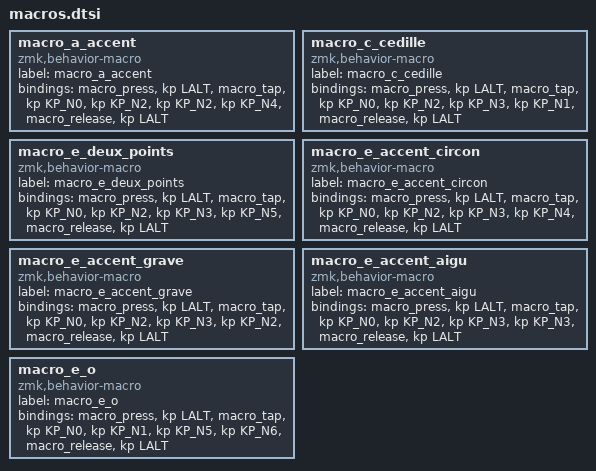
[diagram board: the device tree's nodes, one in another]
macro_a_accent: macro_a_accent{
compatible = "zmk,behavior-macro";
label = "macro_a_accent";
#binding-cells = <0>;
bindings = <&macro_press &kp LALT>, <&macro_tap &kp KP_N0 &kp KP_N2 &kp KP_N2 &kp KP_N4>, <&macro_release &kp LALT>;
};
macro_c_cedille: macro_c_cedille{
compatible = "zmk,behavior-macro";
label = "macro_c_cedille";
#binding-cells = <0>;
bindings = <&macro_press &kp LALT>, <&macro_tap &kp KP_N0 &kp KP_N2 &kp KP_N3 &kp KP_N1>, <&macro_release &kp LALT>;
};
macro_e_deux_points: macro_e_deux_points{
compatible = "zmk,behavior-macro";
label = "macro_e_deux_points";
#binding-cells = <0>;
bindings = <&macro_press &kp LALT>, <&macro_tap &kp KP_N0 &kp KP_N2 &kp KP_N3 &kp KP_N5>, <&macro_release &kp LALT>;
};
macro_e_accent_circon: macro_e_accent_circon{
compatible = "zmk,behavior-macro";
label = "macro_e_accent_circon";
#binding-cells = <0>;
bindings = <&macro_press &kp LALT>, <&macro_tap &kp KP_N0 &kp KP_N2 &kp KP_N3 &kp KP_N4>, <&macro_release &kp LALT>;
};
macro_e_accent_grave: macro_e_accent_grave{
compatible = "zmk,behavior-macro";
label = "macro_e_accent_grave";
#binding-cells = <0>;
bindings = <&macro_press &kp LALT>, <&macro_tap &kp KP_N0 &kp KP_N2 &kp KP_N3 &kp KP_N2>, <&macro_release &kp LALT>;
};
macro_e_accent_aigu: macro_e_accent_aigu{
compatible = "zmk,behavior-macro";
label = "macro_e_accent_aigu";
#binding-cells = <0>;
bindings = <&macro_press &kp LALT>, <&macro_tap &kp KP_N0 &kp KP_N2 &kp KP_N3 &kp KP_N3>, <&macro_release &kp LALT>;
};
macro_e_o: macro_e_o{
compatible = "zmk,behavior-macro";
label = "macro_e_o";
#binding-cells = <0>;
bindings = <&macro_press &kp LALT>, <&macro_tap &kp KP_N0 &kp KP_N1 &kp KP_N5 &kp KP_N6>, <&macro_release &kp LALT>;
};
